# CORE_PRM register map
Vendor: Texas Instruments
Peripheral module from a debugger description file (folder omap34xx).
Registers are 32-bit, access per field, reset 0xC33FFE18 unless marked. A register's access mark holds for its fields unless they carry their own. Offsets are as the file gives them; lines under a group give offsets from that group; [hi:lo] are bit positions; {n}, {i} and the like mark numbered series; 'fields as' and 'values as' point back to an identical list; <NAME> marks a mode.

## CORE_PRM
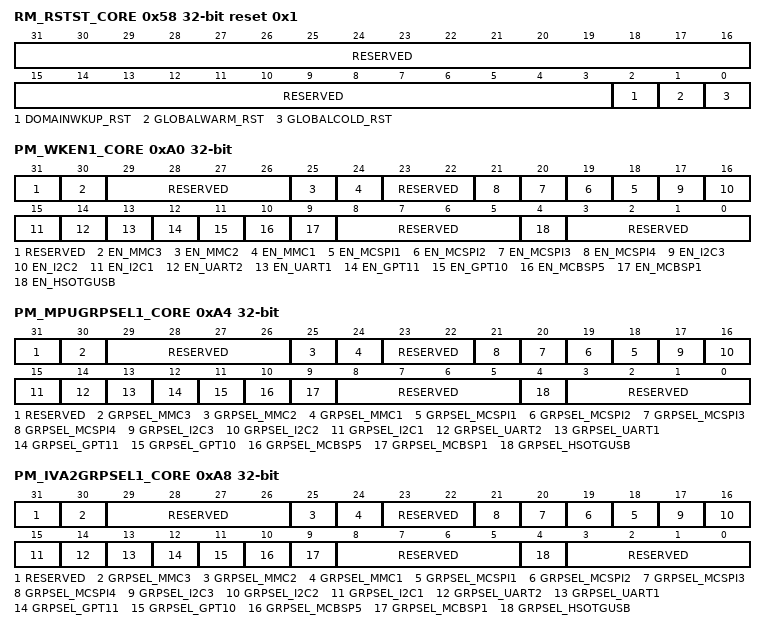
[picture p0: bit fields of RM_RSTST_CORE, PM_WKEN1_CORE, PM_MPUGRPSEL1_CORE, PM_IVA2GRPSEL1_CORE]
0x58 RM_RSTST_CORE reset 0x1 — This register logs the different reset sources of the CORE domain. Each bit is set upon release of the domain reset signal. Must be cleared by software.
  [31:3] RESERVED ro — Write 0s for future compatibility. Read returns 0.
  [2] DOMAINWKUP_RST rw — Power domain wake-up reset
    0=DOMAINWKUP_RST_0_r (No power domain wake-up reset.); 0=DOMAINWKUP_RST_0_w (Status bit unchanged); 1=DOMAINWKUP_RST_1_r (CORE domain has been reset following a CORE power domain wake-up.); 1=DOMAINWKUP_RST_1_w (Status bit is cleared to 0.)
  [1] GLOBALWARM_RST rw — Global warm reset
    0=GLOBALWARM_RST_0_r (No global warm reset.); 0=GLOBALWARM_RST_0_w (Status bit unchanged); 1=GLOBALWARM_RST_1_r (CORE domain has been reset upon a global warm reset); 1=GLOBALWARM_RST_1_w (Status bit is cleared to 0.)
  [0] GLOBALCOLD_RST rw — Global cold reset
    0=GLOBALCOLD_RST_0_r (No global cold reset.); 0=GLOBALCOLD_RST_0_w (Status bit unchanged); 1=GLOBALCOLD_RST_1_r (CORE domain has been reset upon a global cold reset); 1=GLOBALCOLD_RST_1_w (Status bit is cleared to 0.)
0xA0 PM_WKEN1_CORE — This register allows enabling/disabling modules wake-up events.
  [31] RESERVED rw — Write 1's for future compatibility. Read returns 1.
  [30] EN_MMC3 rw — MMC SDIO 3 wake-up control
    0=MMC 3 wake-up is disabled; 1=MMC 3 wake-up event is enabled
  [29:26] RESERVED ro — Write 0s for future compatibility. Read returns 0.
  [25] EN_MMC2 rw — MMC SDIO 2 wake-up control
    0=MMC 2 wake-up is disabled; 1=MMC 2 wake-up event is enabled
  [24] EN_MMC1 rw — MMC SDIO 1 wake-up control
    0=MMC 1 wake-up is disabled; 1=MMC 1 wake-up event is enabled
  [23:22] RESERVED ro — Write 0s for future compatibility. Read returns 0.
  [n+17] EN_MCSPI{n} rw (n=1..4) — McSPI {n} wake-up control
    0=McSPI {n} wake-up is disabled; 1=McSPI {n} wake-up event is enabled
  [17] EN_I2C3 rw — I2C 3 wake-up control
    0=I2C 3 wake-up is disabled; 1=I2C 3 wake-up event is enabled
  [16] EN_I2C2 rw — I2C 2 wake-up control
    0=I2C 2 wake-up is disabled; 1=I2C 2 wake-up event is enabled
  [15] EN_I2C1 rw — I2C 1 wake-up control
    0=I2C 1 wake-up is disabled; 1=I2C 1 wake-up event is enabled
  [14] EN_UART2 rw — UART 2 wake-up control
    0=UART 2 wake-up is disabled; 1=UART 2 wake-up event is enabled
  [13] EN_UART1 rw — UART 1 wake-up control
    0=UART 1 wake-up is disabled; 1=UART 1 wake-up event is enabled
  [12] EN_GPT11 rw — GPTIMER 11 wake-up control
    0=GPTIMER 11 wake-up is disabled; 1=GPTIMER 11 wake-up event is enabled
  [11] EN_GPT10 rw — GPTIMER 10 wake-up control
    0=GPTIMER 10 wake-up is disabled; 1=GPTIMER 10 wake-up event is enabled
  [10] EN_MCBSP5 rw — McBSP 5 wake-up control
    0=McBSP 5 wake-up is disabled; 1=McBSP 5 wake-up event is enabled
  [9] EN_MCBSP1 rw — McBSP 1 wake-up control
    0=McBSP 1 wake-up is disabled; 1=McBSP 1 wake-up event is enabled
  [8:5] RESERVED ro — Write 0s for future compatibility. Read returns 0.
  [4] EN_HSOTGUSB rw — HS OTG USB wake-up control
    0=HS OTG USB wake-up is disabled; 1=HS OTG USB wake-up event is enabled
  [3:0] RESERVED ro — Write 0x8 for future compatibility. Read returns 0x8.
0xA4 PM_MPUGRPSEL1_CORE — This register allows selecting the group of modules that wake-up the MPU.
  [31] RESERVED rw — Write 1's for future compatibility. Read returns 1.
  [30] GRPSEL_MMC3 rw — Select the MMC 3 in the MPU wake-up events group
    0=MMC 3 is not attached to the MPU wake-up events group; 1=MMC 3 is attached to the MPU wake-up events group
  [29:26] RESERVED ro — Write 0s for future compatibility. Read returns 0.
  [25] GRPSEL_MMC2 rw — Select the MMC 2 in the MPU wake-up events group
    0=MMC 2 is not attached to the MPU wake-up events group; 1=MMC 2 is attached to the MPU wake-up events group
  [24] GRPSEL_MMC1 rw — Select the MMC 1 in the MPU wake-up events group
    0=MMC 1 is not attached to the MPU wake-up events group; 1=MMC 1 is attached to the MPU wake-up events group
  [23:22] RESERVED ro — Write 0s for future compatibility. Read returns 0.
  [n+17] GRPSEL_MCSPI{n} rw (n=1..4) — Select the McSPI {n} in the MPU wake-up events group
    0=McSPI {n} is not attached to the MPU wake-up events group; 1=McSPI {n} is attached to the MPU wake-up events group
  [17] GRPSEL_I2C3 rw — Select the I2C 3 in the MPU wake-up events group
    0=I2C 3 is not attached to the MPU wake-up events group; 1=I2C 3 is attached to the MPU wake-up events group
  [16] GRPSEL_I2C2 rw — Select the I2C 2 in the MPU wake-up events group
    0=I2C 2 is not attached to the MPU wake-up events group; 1=I2C 2 is attached to the MPU wake-up events group
  [15] GRPSEL_I2C1 rw — Select the I2C 1 in the MPU wake-up events group
    0=I2C 1 is not attached to the MPU wake-up events group; 1=I2C 1 is attached to the MPU wake-up events group
  [14] GRPSEL_UART2 rw — Select the UART 2 in the MPU wake-up events group
    0=UART 2 is not attached to the MPU wake-up events group; 1=UART 2 is attached to the MPU wake-up events group
  [13] GRPSEL_UART1 rw — Select the UART 1 in the MPU wake-up events group
    0=UART 1 is not attached to the MPU wake-up events group; 1=UART 1 is attached to the MPU wake-up events group
  [12] GRPSEL_GPT11 rw — Select the GPTIMER 11 in the MPU wake-up events group
    0=GPTIMER 11 is not attached to the MPU wake-up events group; 1=GPTIMER 11 is attached to the MPU wake-up events group
  [11] GRPSEL_GPT10 rw — Select the GPTIMER 10 in the MPU wake-up events group
    0=GPTIMER 10 is not attached to the MPU wake-up events group; 1=GPTIMER 10 is attached to the MPU wake-up events group
  [10] GRPSEL_MCBSP5 rw — Select the McBSP 5 in the MPU wake-up events group
    0=McBSP 5 is not attached to the MPU wake-up events group; 1=McBSP 5 is attached to the MPU wake-up events group
  [9] GRPSEL_MCBSP1 rw — Select the McBSP 1 in the MPU wake-up events group
    0=McBSP 1 is not attached to the MPU wake-up events group; 1=McBSP 1 is attached to the MPU wake-up events group
  [8:5] RESERVED ro — Write 0s for future compatibility. Read returns 0.
  [4] GRPSEL_HSOTGUSB rw — Select the HS OTG USB in the MPU wake-up events group
    0=HS OTG USB is not attached to the MPU wake-up events group; 1=HS OTG USB is attached to the MPU wake-up events group
  [3:0] RESERVED ro — Write 0x8 for future compatibility. Read returns 0x8.
0xA8 PM_IVA2GRPSEL1_CORE — This register allows selecting the group of modules that wake-up the IVA2.
  [31] RESERVED rw — Write 1's for future compatibility. Read returns 1.
  [30] GRPSEL_MMC3 rw — Select the MMC 3 in the IVA2 wake-up events group
    0=MMC 3 is not attached to the IVA2 wake-up events group; 1=MMC 3 is attached to the IVA2 wake-up events group
  [29:26] RESERVED ro — Write 0s for future compatibility. Read returns 0.
  [25] GRPSEL_MMC2 rw — Select the MMC 2 in the IVA2 wake-up events group
    0=MMC 2 is not attached to the IVA2 wake-up events group; 1=MMC 2 is attached to the IVA2 wake-up events group
  [24] GRPSEL_MMC1 rw — Select the MMC 1 in the IVA2 wake-up events group
    0=MMC 1 is not attached to the IVA2 wake-up events group; 1=MMC 1 is attached to the IVA2 wake-up events group
  [23:22] RESERVED ro — Write 0s for future compatibility. Read returns 0.
  [n+17] GRPSEL_MCSPI{n} rw (n=1..4) — Select the McSPI {n} in the IVA2 wake-up events group
    0=McSPI {n} is not attached to the IVA2 wake-up events group; 1=McSPI {n} is attached to the IVA2 wake-up events group
  [17] GRPSEL_I2C3 rw — Select the I2C 3 in the IVA2 wake-up events group
    0=I2C 3 is not attached to the IVA2 wake-up events group; 1=I2C 3 is attached to the IVA2 wake-up events group
  [16] GRPSEL_I2C2 rw — Select the I2C 2 in the IVA2 wake-up events group
    0=I2C 2 is not attached to the IVA2 wake-up events group; 1=I2C 2 is attached to the IVA2 wake-up events group
  [15] GRPSEL_I2C1 rw — Select the I2C 1 in the IVA2 wake-up events group
    0=I2C 1 is not attached to the IVA2 wake-up events group; 1=I2C 1 is attached to the IVA2 wake-up events group
  [14] GRPSEL_UART2 rw — Select the UART 2 in the IVA2 wake-up events group
    0=UART 2 is not attached to the IVA2 wake-up events group; 1=UART 2 is attached to the IVA2 wake-up events group
  [13] GRPSEL_UART1 rw — Select the UART 1 in the IVA2 wake-up events group
    0=UART 1 is not attached to the IVA2 wake-up events group; 1=UART 1 is attached to the IVA2 wake-up events group
  [12] GRPSEL_GPT11 rw — Select the GPTIMER 11 in the IVA2 wake-up events group
    0=GPTIMER 11 is not attached to the IVA2 wake-up events group; 1=GPTIMER 11 is attached to the IVA2 wake-up events group
  [11] GRPSEL_GPT10 rw — Select the GPTIMER 10 in the IVA2 wake-up events group
    0=GPTIMER 10 is not attached to the IVA2 wake-up events group; 1=GPTIMER 10 is attached to the IVA2 wake-up events group
  [10] GRPSEL_MCBSP5 rw — Select the McBSP 5 in the IVA2 wake-up events group
    0=McBSP 5 is not attached to the IVA2 wake-up events group; 1=McBSP 5 is attached to the IVA2 wake-up events group
  [9] GRPSEL_MCBSP1 rw — Select the McBSP 1 in the IVA2 wake-up events group
    0=McBSP 1 is not attached to the IVA2 wake-up events group; 1=McBSP 1 is attached to the IVA2 wake-up events group
  [8:5] RESERVED ro — Write 0s for future compatibility. Read returns 0.
  [4] GRPSEL_HSOTGUSB rw — Select the HS OTG USB in the IVA2 wake-up events group
    0=HS OTG USB is not attached to the IVA2 wake-up events group; 1=HS OTG USB is attached to the IVA2 wake-up events group
  [3:0] RESERVED ro — Write 0x8 for future compatibility. Read returns 0x8.
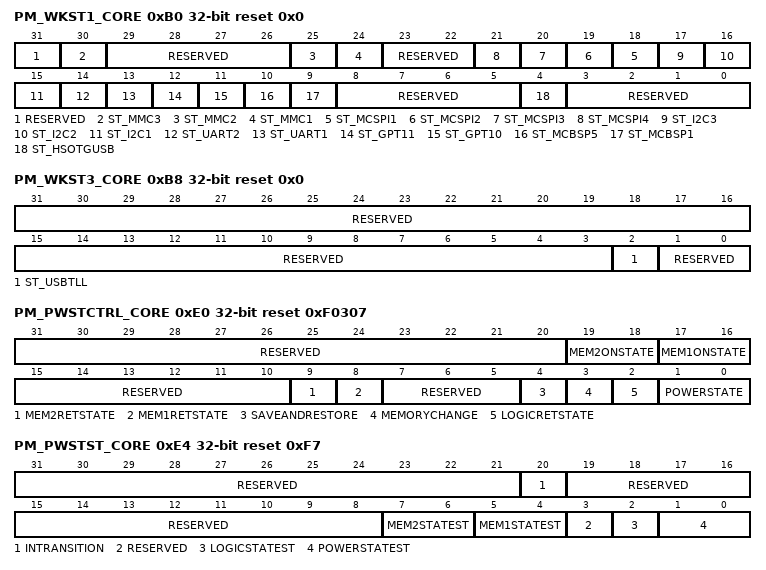
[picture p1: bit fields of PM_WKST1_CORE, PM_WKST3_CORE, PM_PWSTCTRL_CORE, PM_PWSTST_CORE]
0xB0 PM_WKST1_CORE reset 0x0 — This register logs module wake-up events. Must be cleared by software. If it is not cleared, it prevents further domain transition.
  [31] RESERVED rw — Write 0s for future compatibility. Read returns 0.
  [30] ST_MMC3 rw — MMC 3 Wake-up status
    0=ST_MMC3_0_r (MMC 3 wake-up did not occur or was masked.); 0=ST_MMC3_0_w (Status bit unchanged); 1=ST_MMC3_1_r (MMC 3 wake-up occurred.); 1=ST_MMC3_1_w (Status bit is cleared to 0.)
  [29:26] RESERVED ro — Write 0s for future compatibility. Read returns 0.
  [25] ST_MMC2 rw — MMC 2 Wake-up status
    0=ST_MMC2_0_r (MMC 2 wake-up did not occur or was masked.); 0=ST_MMC2_0_w (Status bit unchanged); 1=ST_MMC2_1_r (MMC 2 wake-up occurred.); 1=ST_MMC2_1_w (Status bit is cleared to 0.)
  [24] ST_MMC1 rw — MMC 1 Wake-up status
    0=ST_MMC1_0_r (MMC 1 wake-up did not occur or was masked.); 0=ST_MMC1_0_w (Status bit unchanged); 1=ST_MMC1_1_r (MMC 1 wake-up occurred.); 1=ST_MMC1_1_w (Status bit is cleared to 0.)
  [23:22] RESERVED ro — Write 0s for future compatibility. Read returns 0.
  [n+17] ST_MCSPI{n} rw (n=1..4) — McSPI {n} Wake-up status
    0=ST_MCSPI{n}_0_r (McSPI {n} wake-up did not occur or was masked.); 0=ST_MCSPI{n}_0_w (Status bit unchanged); 1=ST_MCSPI{n}_1_r (McSPI {n} wake-up occurred.); 1=ST_MCSPI{n}_1_w (Status bit is cleared to 0.)
  [17] ST_I2C3 rw — I2C 3 Wake-up status
    0=ST_I2C3_0_r (I2C 3 wake-up did not occur or was masked.); 0=ST_I2C3_0_w (Status bit unchanged); 1=ST_I2C3_1_r (I2C 3 wake-up occurred.); 1=ST_I2C3_1_w (Status bit is cleared to 0.)
  [16] ST_I2C2 rw — I2C 2 Wake-up status
    0=ST_I2C2_0_r (I2C 2 wake-up did not occur or was masked.); 0=ST_I2C2_0_w (Status bit unchanged); 1=ST_I2C2_1_r (I2C 2 wake-up occurred.); 1=ST_I2C2_1_w (Status bit is cleared to 0.)
  [15] ST_I2C1 rw — I2C 1 Wake-up status
    0=ST_I2C1_0_r (I2C 1 wake-up did not occur or was masked.); 0=ST_I2C1_0_w (Status bit unchanged); 1=ST_I2C1_1_r (I2C 1 wake-up occurred.); 1=ST_I2C1_1_w (Status bit is cleared to 0.)
  [14] ST_UART2 rw — UART 2 Wake-up status
    0=ST_UART2_0_r (UART 2 wake-up did not occur or was masked.); 0=ST_UART2_0_w (Status bit unchanged); 1=ST_UART2_1_r (UART 2 wake-up occurred.); 1=ST_UART2_1_w (Status bit is cleared to 0.)
  [13] ST_UART1 rw — UART 1 Wake-up status
    0=ST_UART1_0_r (UART 1 wake-up did not occur or was masked.); 0=ST_UART1_0_w (Status bit unchanged); 1=ST_UART1_1_r (UART 1 wake-up occurred.); 1=ST_UART1_1_w (Status bit is cleared to 0.)
  [12] ST_GPT11 rw — GPTIMER 11 Wake-up status
    0=ST_GPT11_0_r (GPTIMER 11 wake-up did not occur or was masked.); 0=ST_GPT11_0_w (Status bit unchanged); 1=ST_GPT11_1_r (Status bit is cleared to 0.); 1=ST_GPT11_1_w (GPTIMER 11 wake-up occurred.)
  [11] ST_GPT10 rw — GPTIMER 10 Wake-up status
    0=ST_GPT10_0_r (GPTIMER 10 wake-up did not occur or was masked.); 0=ST_GPT10_0_w (Status bit unchanged); 1=ST_GPT10_1_r (GPTIMER 10 wake-up occurred.); 1=ST_GPT10_1_w (Status bit is cleared to 0.)
  [10] ST_MCBSP5 rw — McBSP 5 Wake-up status
    0=ST_MCBSP5_0_r (McBSP 5 wake-up did not occur or was masked.); 0=ST_MCBSP5_0_w (Status bit unchanged); 1=ST_MCBSP5_1_r (McBSP 5 wake-up occurred.); 1=ST_MCBSP5_1_w (Status bit is cleared to 0.)
  [9] ST_MCBSP1 rw — McBSP 1 Wake-up status
    0=ST_MCBSP1_0_r (McBSP 1 wake-up did not occur or was masked.); 0=ST_MCBSP1_0_w (Status bit unchanged); 1=ST_MCBSP1_1_r (McBSP 1 wake-up occurred.); 1=ST_MCBSP1_1_w (Status bit is cleared to 0.)
  [8:5] RESERVED ro — Write 0s for future compatibility. Read returns 0.
  [4] ST_HSOTGUSB rw — HS OTG USB Wake-up status
    0=ST_HSOTGUSB_0_r (HS OTG USB wake-up did not occur or was masked.); 0=ST_HSOTGUSB_0_w (Status bit unchanged); 1=ST_HSOTGUSB_1_r (HS OTG USB wake-up occurred.); 1=ST_HSOTGUSB_1_w (Status bit is cleared to 0.)
  [3:0] RESERVED ro — Write 0s for future compatibility. Read returns 0.
0xB8 PM_WKST3_CORE reset 0x0 — This register logs module wake-up events. Must be cleared by software. If it is not cleared, it prevents further domain transition.
  [31:3] RESERVED ro — Write 0s for future compatibility. Read returns 0.
  [2] ST_USBTLL rw — USB TLL wake-up status
    0=ST_USBTLL_0_r (USB TLL wake-up did not occur or was masked.); 0=ST_USBTLL_0_w (Status bit unchanged); 1=ST_USBTLL_1_r (USB TLL wake-up occurred.); 1=ST_USBTLL_1_w (Status bit is cleared to 0.)
  [1:0] RESERVED ro — Write 0s for future compatibility. Read returns 0.
0xE0 PM_PWSTCTRL_CORE reset 0xF0307 — This register controls the CORE domain power state transition.
  [31:20] RESERVED ro — Write 0s for future compatibility. Read returns 0.
  [19:18] MEM2ONSTATE rw — Memory block 2 state when domain is ON
    0=Memory block 2 is OFF when domain is ON; 1=Memory block 2 is in RETENTION when domain is ON; 3=Memory block 2 is ON when domain is ON
  [17:16] MEM1ONSTATE rw — Memory block 1 state when domain is ON
    0=Memory block 1 is OFF when domain is ON; 1=Memory block 1 is in RETENTION when domain is ON; 3=Memory block 1 is ON when domain is ON
  [15:10] RESERVED ro — Write 0s for future compatibility. Read returns 0.
  [9] MEM2RETSTATE rw — Memory block 2 state when domain is RETENTION
    0=Memory block 2 is OFF when domain is in RETENTION state; 1=Memory block 2 is retained when domain is in RETENTION state
  [8] MEM1RETSTATE rw — Memory block 1 state when domain is RETENTION
    0=Memory block 1 is OFF when domain is in RETENTION state; 1=Memory block 1 is retained when domain is in RETENTION state
  [7:5] RESERVED ro — Write 0s for future compatibility. Read returns 0.
  [4] SAVEANDRESTORE rw — Save And Restore mechanism for the USB TLL module
    0=Disable the save and restore mechanism for the USB TLL module; 1=Enable the save and restore mechanism for the USB TLL module
  [3] MEMORYCHANGE rw — Memory change control in ON state
    0=Disable memory change; 1=Enable memory change state in ON state. This bit is automaticaly cleared when memory state is effectively changed.
  [2] LOGICRETSTATE rw — Logic state when domain is RETENTION
    0=Logic build with retention flip-flop (SMS, SDRC, control module, clock management) is retained and remaining logic is OFF when domain is in RETENTION state; 1=Logic is retained when domain is in RETENTION state
  [1:0] POWERSTATE rw — Power state control
    0=OFF state; 1=RETENTION state; 3=ON state
0xE4 PM_PWSTST_CORE ro reset 0xF7 — This register provides a status on the power state transition of the CORE domain.
  [31:21] RESERVED — Read returns 0.
  [20] INTRANSITION — Domain transition status
    0=No transition; 1=CORE power domain transition is in progress
  [19:8] RESERVED — Read returns 0.
  [7:6] MEM2STATEST — Memory block 2 state status
    0=Memory is OFF; 1=Memory is in RETENTION; 3=Memory is ON
  [5:4] MEM1STATEST — Memory block 1 state status
    0=Memory is OFF; 1=Memory is in RETENTION; 3=Memory is ON
  [3] RESERVED — Read returns 0.
  [2] LOGICSTATEST — Logic state status
    0=CORE domain logic is OFF; 1=CORE domain logic is ON
  [1:0] POWERSTATEST — Current power state status
    0=Power domain is OFF; 1=Power domain is in RETENTION; 2=Power domain is INACTIVE; 3=Power domain is ON
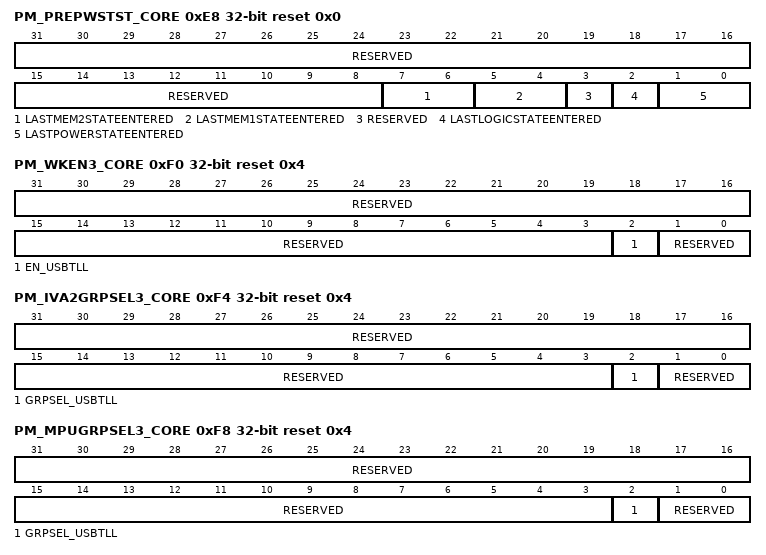
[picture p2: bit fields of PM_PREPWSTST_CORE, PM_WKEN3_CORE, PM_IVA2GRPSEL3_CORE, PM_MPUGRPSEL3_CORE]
0xE8 PM_PREPWSTST_CORE reset 0x0 — This register provides a status on the CORE domain previous power state. It indicates the state entered during the last sleep transition.
  [31:8] RESERVED ro — Read returns 0.
  [7:6] LASTMEM2STATEENTERED rw — Last Memory block 2 state entered
    0=Memory was previously OFF; 1=Memory was previously in RETENTION; 3=Memory was previously ON
  [5:4] LASTMEM1STATEENTERED rw — Last Memory block 1 state entered
    values as LASTMEM2STATEENTERED
  [3] RESERVED ro — Read returns 0.
  [2] LASTLOGICSTATEENTERED rw
    0=CORE domain logic was previously OFF; 1=CORE domain logic was previously ON
  [1:0] LASTPOWERSTATEENTERED rw
    0=CORE domain was previously OFF; 1=CORE domain was previously in RETENTION; 2=CORE domain was previously INACTIVE; 3=CORE domain was previously ON
0xF0 PM_WKEN3_CORE reset 0x4 — This register allows enabling/disabling modules wake-up events.
  [31:3] RESERVED ro — Write 0s for future compatibility. Read returns 0.
  [2] EN_USBTLL rw — USB TLL wake-up control
    0=USB TLL wake-up is disabled; 1=USB TLL wake-up event is enabled
  [1:0] RESERVED ro — Write 0s for future compatibility. Read returns 0.
0xF4 PM_IVA2GRPSEL3_CORE reset 0x4 — This register allows selecting the group of modules that wake-up the IVA2.
  [31:3] RESERVED ro — Write 0s for future compatibility. Read returns 0.
  [2] GRPSEL_USBTLL rw — Select the USB TLL in the IVA2 wake-up events group
    0=USB TLL is not attached to the IVA2 wake-up events group; 1=USB TLL is attached to the IVA2 wake-up events group
  [1:0] RESERVED ro — Write 0s for future compatibility. Read returns 0.
0xF8 PM_MPUGRPSEL3_CORE reset 0x4 — This register allows selecting the group of modules that wake-up the MPU.
  [31:3] RESERVED ro — Write 0s for future compatibility. Read returns 0.
  [2] GRPSEL_USBTLL rw — Select the USB TLL in the MPU wake-up events group
    0=USB TLL is not attached to the MPU wake-up events group; 1=USB TLL is attached to the MPU wake-up events group
  [1:0] RESERVED ro — Write 0s for future compatibility. Read returns 0.
